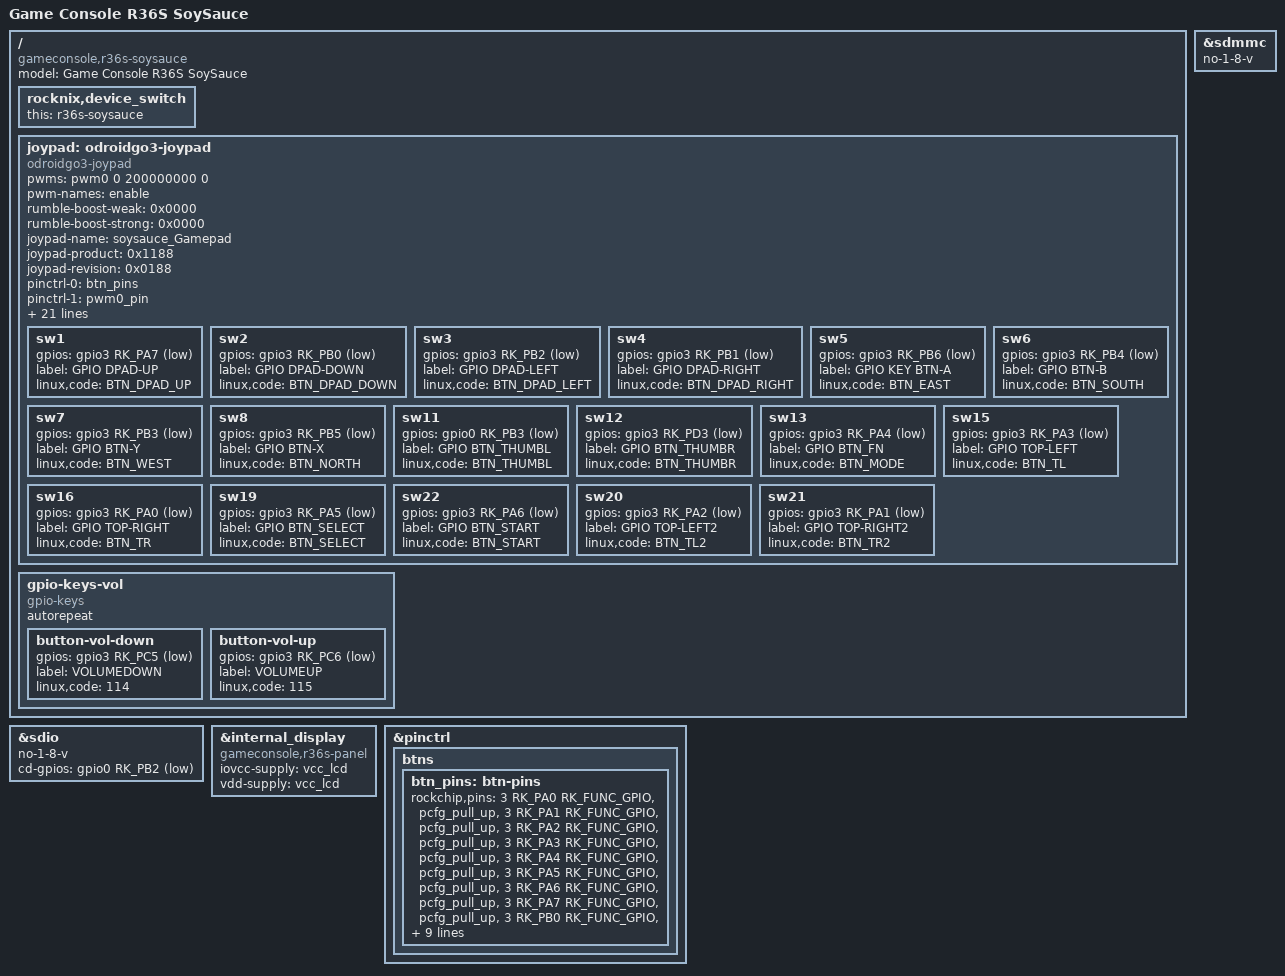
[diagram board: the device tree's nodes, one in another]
// SPDX-License-Identifier: (GPL-2.0+ OR MIT)
/*
 * Y3506 "SoySauce" R36S clone - batch 2601
 * 
 * Based on rk3326-gameconsole-r3xs.dtsi (same as r36s.dts)
 * GPIO assignments from Y3506 vendor (darkos) DTB, translated to mainline notation.
 *
 * Key differences from genuine R36S:
 *   - ALL button GPIOs are on gpio3 (not gpio1/gpio2 like R36S)
 *   - THUMBL button is on gpio0 PB3 (not gpio2)
 *   - AMux GPIOs are on gpio0 (not gpio3 like R36S)
 *   - SD cards: no-1-8-v (no UHS support)
 *   - Joypad ADC channels swapped: amux-channel-mapping = <3 2 0 1>
 *   - Panel: same as R36S (elida kd35t133 / st7703)
 */

/dts-v1/;
#include "rk3326-gameconsole-r3xs.dtsi"
#include "rk3326-device-group-r36.dtsi"

/ {
	model = "Game Console R36S SoySauce";
	compatible = "gameconsole,r36s-soysauce", "gameconsole,r36s", "rockchip,rk3326";

	rocknix,device_switch {
		this = "r36s-soysauce";
	};

	joypad: odroidgo3-joypad {
		compatible = "odroidgo3-joypad";
		pwms = <&pwm0 0 200000000 0>;
		pwm-names = "enable";
		rumble-boost-weak = <0x0000>;
		rumble-boost-strong = <0x0000>;

		joypad-name = "soysauce_Gamepad";
		joypad-product = <0x1188>;
		joypad-revision = <0x0188>;

		status = "okay";

		/* gpio pincontrol setup */
		pinctrl-names = "default";
		pinctrl-0 = <&btn_pins>;
		pinctrl-1 = <&pwm0_pin>;

		/* Analog mux define */
		io-channel-names = "amux_adc";
		io-channels = <&saradc 1>;

		/* adc mux channel count */
		amux-count = <4>;

		/* Y3506: amux GPIOs on gpio0 (NOT gpio3 like R36S) */
		amux-a-gpios = <&gpio0 RK_PB5 GPIO_ACTIVE_LOW>;
		amux-b-gpios = <&gpio0 RK_PB4 GPIO_ACTIVE_LOW>;
		amux-en-gpios = <&gpio0 RK_PC1 GPIO_ACTIVE_LOW>;

		/* Y3506: ADC channels are swapped on this PCB */
		amux-channel-mapping = <3 2 0 1>;

		/* adc calculate scale */
		button-adc-scale = <2>;
		button-adc-deadzone = <64>;
		button-adc-fuzz = <32>;
		button-adc-flat = <32>;

		abs_x-p-tuning = <200>;
		abs_x-n-tuning = <200>;
		abs_y-p-tuning = <200>;
		abs_y-n-tuning = <200>;
		abs_rx-p-tuning = <200>;
		abs_rx-n-tuning = <200>;
		abs_ry-p-tuning = <200>;
		abs_ry-n-tuning = <200>;

		/* poll device interval (ms) */
		poll-interval = <10>;

		/* Y3506: same axis inversion as R36S */
		invert-absx;
		invert-absy;

		/*
		 * Y3506 button GPIO mapping
		 * ALL buttons are on gpio3 except THUMBL which is on gpio0
		 * (R36S uses gpio1 for face/dpad, gpio2 for shoulders)
		 *
		 * Vendor DTB phandle 0x63 = gpio3@ff270000
		 * Vendor DTB phandle 0x59 = gpio0@ff040000
		 */

		/* D-pad: all on gpio3 */
		sw1 {
			gpios = <&gpio3 RK_PA7 GPIO_ACTIVE_LOW>;
			label = "GPIO DPAD-UP";
			linux,code = <BTN_DPAD_UP>;
		};
		sw2 {
			gpios = <&gpio3 RK_PB0 GPIO_ACTIVE_LOW>;
			label = "GPIO DPAD-DOWN";
			linux,code = <BTN_DPAD_DOWN>;
		};
		sw3 {
			gpios = <&gpio3 RK_PB2 GPIO_ACTIVE_LOW>;
			label = "GPIO DPAD-LEFT";
			linux,code = <BTN_DPAD_LEFT>;
		};
		sw4 {
			gpios = <&gpio3 RK_PB1 GPIO_ACTIVE_LOW>;
			label = "GPIO DPAD-RIGHT";
			linux,code = <BTN_DPAD_RIGHT>;
		};

		/* Face buttons: all on gpio3 */
		sw5 {
			gpios = <&gpio3 RK_PB6 GPIO_ACTIVE_LOW>;
			label = "GPIO KEY BTN-A";
			linux,code = <BTN_EAST>;
		};
		sw6 {
			gpios = <&gpio3 RK_PB4 GPIO_ACTIVE_LOW>;
			label = "GPIO BTN-B";
			linux,code = <BTN_SOUTH>;
		};
		sw7 {
			gpios = <&gpio3 RK_PB3 GPIO_ACTIVE_LOW>;
			label = "GPIO BTN-Y";
			linux,code = <BTN_WEST>;
		};
		sw8 {
			gpios = <&gpio3 RK_PB5 GPIO_ACTIVE_LOW>;
			label = "GPIO BTN-X";
			linux,code = <BTN_NORTH>;
		};

		/* Thumbstick buttons */
		sw11 {
			gpios = <&gpio0 RK_PB3 GPIO_ACTIVE_LOW>;
			label = "GPIO BTN_THUMBL";
			linux,code = <BTN_THUMBL>;
		};
		sw12 {
			gpios = <&gpio3 RK_PD3 GPIO_ACTIVE_LOW>;
			label = "GPIO BTN_THUMBR";
			linux,code = <BTN_THUMBR>;
		};

		/* Function/mode button */
		sw13 {
			gpios = <&gpio3 RK_PA4 GPIO_ACTIVE_LOW>;
			label = "GPIO BTN_FN";
			linux,code = <BTN_MODE>;
		};

		/* Shoulder buttons: all on gpio3 */
		sw15 {
			gpios = <&gpio3 RK_PA3 GPIO_ACTIVE_LOW>;
			label = "GPIO TOP-LEFT";
			linux,code = <BTN_TL>;
		};
		sw16 {
			gpios = <&gpio3 RK_PA0 GPIO_ACTIVE_LOW>;
			label = "GPIO TOP-RIGHT";
			linux,code = <BTN_TR>;
		};

		/* Select/Start */
		sw19 {
			gpios = <&gpio3 RK_PA5 GPIO_ACTIVE_LOW>;
			label = "GPIO BTN_SELECT";
			linux,code = <BTN_SELECT>;
		};
		sw22 {
			gpios = <&gpio3 RK_PA6 GPIO_ACTIVE_LOW>;
			label = "GPIO BTN_START";
			linux,code = <BTN_START>;
		};

		/* Shoulder 2 */
		sw20 {
			gpios = <&gpio3 RK_PA2 GPIO_ACTIVE_LOW>;
			label = "GPIO TOP-LEFT2";
			linux,code = <BTN_TL2>;
		};
		sw21 {
			gpios = <&gpio3 RK_PA1 GPIO_ACTIVE_LOW>;
			label = "GPIO TOP-RIGHT2";
			linux,code = <BTN_TR2>;
		};
	};
};

/* Y3506: SD card slot 1 - no 1.8V/UHS */
&sdmmc {
	no-1-8-v;
	/delete-property/ sd-uhs-sdr12;
	/delete-property/ sd-uhs-sdr25;
	/delete-property/ sd-uhs-sdr50;
	/delete-property/ sd-uhs-sdr104;
};

/* Y3506: SD card slot 2 - no 1.8V/UHS, fix cd-gpios (r3xs uses GPIO3_PB6
 * which conflicts with joypad BTN-A; vendor uses GPIO0_PB2) */
&sdio {
	no-1-8-v;
	/delete-property/ sd-uhs-sdr12;
	/delete-property/ sd-uhs-sdr25;
	/delete-property/ sd-uhs-sdr50;
	/delete-property/ sd-uhs-sdr104;
	cd-gpios = <&gpio0 RK_PB2 GPIO_ACTIVE_LOW>;
};

/* Y3506: Volume buttons on GPIO3_PC5/PC6 (not GPIO2_PA0/PA1 like R36S) */
/ {
	gpio-keys-vol {
		compatible = "gpio-keys";
		autorepeat;

		button-vol-down {
			gpios = <&gpio3 RK_PC5 GPIO_ACTIVE_LOW>;
			label = "VOLUMEDOWN";
			linux,code = <114>;
		};

		button-vol-up {
			gpios = <&gpio3 RK_PC6 GPIO_ACTIVE_LOW>;
			label = "VOLUMEUP";
			linux,code = <115>;
		};
	};
};

/* Y3506: Same panel as R36S */
&internal_display {
	compatible = "gameconsole,r36s-panel", "sitronix,st7703";
	iovcc-supply = <&vcc_lcd>;
	vdd-supply = <&vcc_lcd>;
};

/* Y3506: Override pinctrl for soysauce GPIO layout */
&pinctrl {
	btns {
		btn_pins: btn-pins {
			rockchip,pins =
				/* D-pad + face buttons + shoulders on gpio3 */
				<3 RK_PA0 RK_FUNC_GPIO &pcfg_pull_up>,
				<3 RK_PA1 RK_FUNC_GPIO &pcfg_pull_up>,
				<3 RK_PA2 RK_FUNC_GPIO &pcfg_pull_up>,
				<3 RK_PA3 RK_FUNC_GPIO &pcfg_pull_up>,
				<3 RK_PA4 RK_FUNC_GPIO &pcfg_pull_up>,
				<3 RK_PA5 RK_FUNC_GPIO &pcfg_pull_up>,
				<3 RK_PA6 RK_FUNC_GPIO &pcfg_pull_up>,
				<3 RK_PA7 RK_FUNC_GPIO &pcfg_pull_up>,
				<3 RK_PB0 RK_FUNC_GPIO &pcfg_pull_up>,
				<3 RK_PB1 RK_FUNC_GPIO &pcfg_pull_up>,
				<3 RK_PB2 RK_FUNC_GPIO &pcfg_pull_up>,
				<3 RK_PB3 RK_FUNC_GPIO &pcfg_pull_up>,
				<3 RK_PB4 RK_FUNC_GPIO &pcfg_pull_up>,
				<3 RK_PB5 RK_FUNC_GPIO &pcfg_pull_up>,
				<3 RK_PB6 RK_FUNC_GPIO &pcfg_pull_up>,
				<3 RK_PD3 RK_FUNC_GPIO &pcfg_pull_up>,
				/* THUMBL on gpio0 */
				<0 RK_PB3 RK_FUNC_GPIO &pcfg_pull_up>;
		};
	};
};
